# STM32WL3xx register map
File version: 1.0
Registers are 32-bit, read-write, reset 0x0 unless marked. A register's access mark holds for its fields unless they carry their own. Offsets are from the block's base; [hi:lo] are bit positions; {n}, {i} and the like mark numbered series.

## LPUART1 — Universal synchronous asynchronous receiver transmitter (USART)
Base 0x41005000
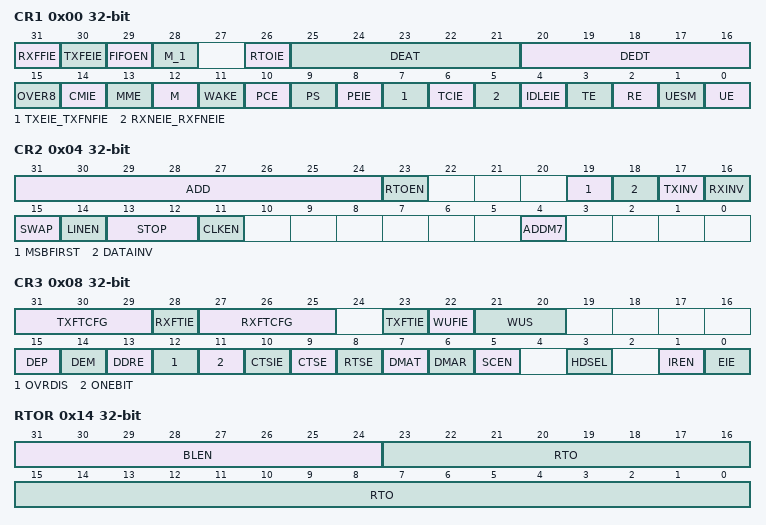
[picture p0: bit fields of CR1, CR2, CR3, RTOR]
0x00 CR1 — (@ 0x00000000) Control register 1
  [31] RXFFIE
  [30] TXFEIE
  [29] FIFOEN
  [28] M_1
  [26] RTOIE
  [25:21] DEAT
  [20:16] DEDT
  [15] OVER8
    0=OVERSAMPLING_16 (Oversampling by 16); 1=OVERSAMPLING_8 (Oversampling by 8)
  [14] CMIE
  [13] MME
  [12] M
  [11] WAKE
    0=IDLELINE (LPUART wake up from Mute mode on Idle Line); 1=ADDRESSMARK (LPUART wake up from Mute mode on Address Mark)
  [10] PCE
  [9] PS
  [8] PEIE
  [7] TXEIE_TXFNFIE
  [6] TCIE
  [5] RXNEIE_RXFNEIE
  [4] IDLEIE
  [3] TE
  [2] RE
  [1] UESM
  [0] UE
0x04 CR2 — (@ 0x00000004) Control register 2
  [31:24] ADD
  [23] RTOEN
  [19] MSBFIRST
    0=LSBFIRST; 1=MSBFIRST
  [18] DATAINV
    0=POSITIVE; 1=NEGATIVE
  [17] TXINV
    0=STANDARD (TX pin signal works using the standard logic levels); 1=INVERTED (TX pin signal values are inverted.)
  [16] RXINV
    0=STANDARD (RX pin signal works using the standard logic levels); 1=INVERTED (RX pin signal values are inverted.)
  [15] SWAP
    0=STANDARD (TX/RX pins are used as defined in standard pinout); 1=SWAPPED (TX and RX pins functions are swapped.)
  [14] LINEN
  [13:12] STOP
    0=STOPBITS_1 (1 stop bit); 2=STOPBITS_2 (2 stop bits); 1=STOPBITS_0_5 (0.5 stop bit); 3=STOPBITS_1_5 (1.5 stop bits)
  [11] CLKEN
  [4] ADDM7
    0=DETECT_4B (4-bit address detection method selected); 1=DETECT_7B (7-bit address detection (in 8-bit data mode) method selected)
0x08 CR3 — (@ 0x00000008) Control register 3
  [31:29] TXFTCFG
  [28] RXFTIE
  [27:25] RXFTCFG
  [23] TXFTIE
  [22] WUFIE
  [21:20] WUS
    0=ADDRESS (Wake up active on address match); 2=STARTBIT (Wake up active on Start bit detection); 3=RXNE (Wake up active on RXNE)
  [15] DEP
    0=HIGH (DE signal is active high); 1=LOW (DE signal is active low)
  [14] DEM
  [13] DDRE
  [12] OVRDIS
  [11] ONEBIT
  [10] CTSIE
  [9] CTSE
  [8] RTSE
  [7] DMAT
  [6] DMAR
  [5] SCEN
  [3] HDSEL
  [1] IREN
  [0] EIE
0x0C BRR — (@ 0x0000000C) Baud rate register
  [19:0] BRR
0x14 RTOR — (@ 0x00000014) Receiver timeout register
  [31:24] BLEN, [23:0] RTO
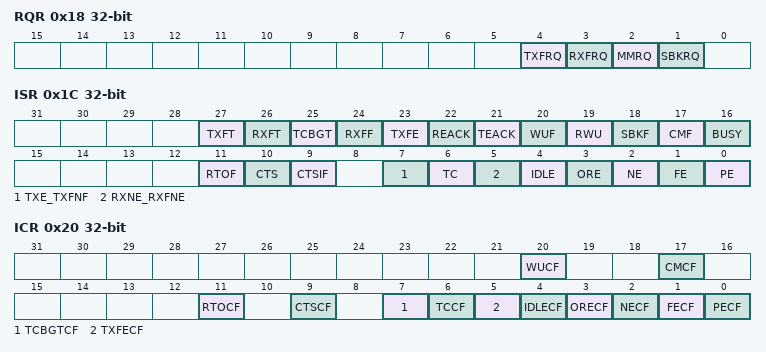
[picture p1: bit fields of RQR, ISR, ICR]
0x18 RQR — (@ 0x00000018) Request register
  [4] TXFRQ, [3] RXFRQ, [2] MMRQ, [1] SBKRQ
0x1C ISR — (@ 0x0000001C) Interrupt & status register
  [27] TXFT, [26] RXFT, [25] TCBGT, [24] RXFF, [23] TXFE, [22] REACK, [21] TEACK, [20] WUF, [19] RWU, [18] SBKF, [17] CMF, [16] BUSY, [11] RTOF, [10] CTS, [9] CTSIF, [7] TXE_TXFNF, [6] TC, [5] RXNE_RXFNE, [4] IDLE, [3] ORE, [2] NE, [1] FE, [0] PE
0x20 ICR — (@ 0x00000020) Interrupt flag clear register
  [20] WUCF, [17] CMCF, [11] RTOCF, [9] CTSCF, [7] TCBGTCF, [6] TCCF, [5] TXFECF, [4] IDLECF, [3] ORECF, [2] NECF, [1] FECF, [0] PECF
0x24 RDR — (@ 0x00000024) Receive data register
  [8:0] RDR
0x28 TDR — (@ 0x00000028) Transmit data register
  [8:0] TDR
0x2C PRESC — (@ 0x0000002C) Prescaler register
  [3:0] PRESCALER
    0=DIV1 (Input clock not divided); 1=DIV2 (Input clock divided by 2); 2=DIV4 (Input clock divided by 4); 3=DIV6; 4=DIV8 (Input clock divided by 8); 5=DIV10; 6=DIV12; 7=DIV16; 8=DIV32 (Input clock divided by 32); 9=DIV64; 10=DIV128; 11=DIV256

## ADC1 — ADC (ADC)
Base 0x41006000
0x00 VERSION_ID — (@ 0x00000000) VERSION_ID register
  [7:0] VERSION_ID
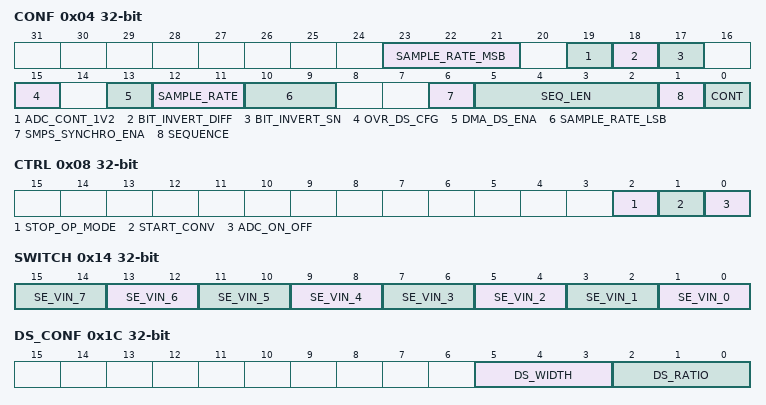
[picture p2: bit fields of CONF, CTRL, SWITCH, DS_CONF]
0x04 CONF — (@ 0x00000004) ADC configuration register
  [23:21] SAMPLE_RATE_MSB
  [19] ADC_CONT_1V2
    0=START; 1=END
  [18] BIT_INVERT_DIFF
  [17] BIT_INVERT_SN
  [15] OVR_DS_CFG
    0=LOST (Previous data is preserved, new data is lost.); 1=KEPT (Previous data is overwritten, new data is kept.)
  [13] DMA_DS_ENA
  [12:11] SAMPLE_RATE
  [10:9] SAMPLE_RATE_LSB
  [6] SMPS_SYNCHRO_ENA
  [5:2] SEQ_LEN
  [1] SEQUENCE
  [0] CONT
0x08 CTRL — (@ 0x00000008) ADC control register
  [2] STOP_OP_MODE, [1] START_CONV, [0] ADC_ON_OFF
0x14 SWITCH — (@ 0x00000014) ADC switch control for Input Selection
  [2n+1:2n] SE_VIN_{n} (n=0..7)
0x1C DS_CONF — (@ 0x0000001C) Downsampler configuration register
  [5:3] DS_WIDTH
  [2:0] DS_RATIO
    0=RATIO_1 (ADC Down Sampler ratio 1, no down sampling (default)); 1=RATIO_2 (ADC Down Sampler ratio 2); 2=RATIO_4 (ADC Down Sampler ratio 4); 3=RATIO_8 (ADC Down Sampler ratio 8); 4=RATIO_16 (ADC Down Sampler ratio 16); 5=RATIO_32 (ADC Down Sampler ratio 32); 6=RATIO_64 (ADC Down Sampler ratio 64); 7=RATIO_128 (ADC Down Sampler ratio 128)
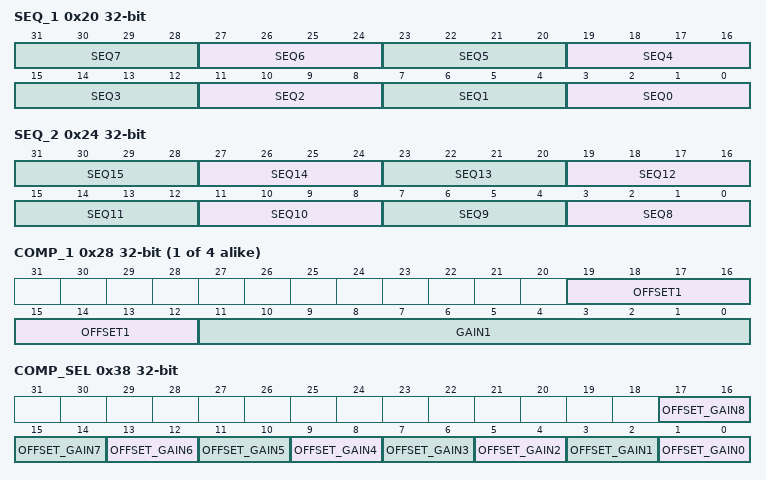
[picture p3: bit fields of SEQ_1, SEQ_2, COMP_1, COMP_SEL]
0x20 SEQ_1 — (@ 0x00000020) ADC regular sequence programming register 1
  [4n+3:4n] SEQ{n} (n=0..7)
0x24 SEQ_2 — (@ 0x00000024) ADC regular sequence programming register 2
  [4n-29:4n-32] SEQ{n} (n=8..15)
{0x24+4i} COMP_{i} (i=1..4) — (@ {0x24+4i}) ADC Gain &
  [19:12] OFFSET{i}, [11:0] GAIN{i}
0x38 COMP_SEL — (@ 0x00000038) ADC Gain &
  [2n+1:2n] OFFSET_GAIN{n} (n=0..8)
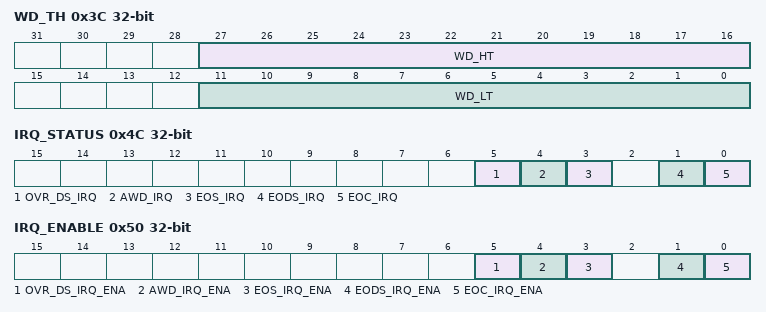
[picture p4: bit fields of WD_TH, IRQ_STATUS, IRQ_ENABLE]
0x3C WD_TH — (@ 0x0000003C) ADC watchdog threshold register register
  [27:16] WD_HT, [11:0] WD_LT
0x40 WD_CONF — (@ 0x00000040) ADC watchdog configuration register
  [15:0] AWD_CHX
    1=VINM0 (ADC watchdog channel selection: VINM0 to negative input); 2=VINM1 (ADC watchdog channel selection: VINM1 to negative input); 4=VINM2 (ADC watchdog channel selection: VINM2 to negative input); 8=VINM3 (ADC watchdog channel selection: VINM3 to negative input); 16=MICROM (ADC watchdog channel selection: MICROM to negative input); 32=VBAT (ADC watchdog channel selection: VBAT to negative input); 64=GND_NEG (ADC watchdog channel selection: GND to negative input); 128=VDDA_NEG (ADC watchdog channel selection: VDDA to negative input); 0x100=VINP0 (ADC watchdog channel selection: VINP0 to positive input); 0x200=VINP1 (ADC watchdog channel selection: VINP1 to positive input); 0x400=VINP2 (ADC watchdog channel selection: VINP2 to positive input); 0x800=VINP3 (ADC watchdog channel selection: VINP3 to positive input); 0x1000=MICROP (ADC watchdog channel selection: MICROP to positive input); 0x2000=TEMPSENSOR (ADC watchdog channel selection: TEMP to positive input); 0x4000=GND_POS (ADC watchdog channel selection: GND to positive input); 0x8000=VDDA_POS (ADC watchdog channel selection: VDDA to positive input)
0x44 DS_DATAOUT — (@ 0x00000044) Downsampler Data output register
  [15:0] DS_DATA
0x4C IRQ_STATUS — (@ 0x0000004C) Interrupt Status register
  [5] OVR_DS_IRQ, [4] AWD_IRQ, [3] EOS_IRQ, [1] EODS_IRQ, [0] EOC_IRQ
0x50 IRQ_ENABLE — (@ 0x00000050) Enable/disable Interrupts
  [5] OVR_DS_IRQ_ENA, [4] AWD_IRQ_ENA, [3] EOS_IRQ_ENA, [1] EODS_IRQ_ENA, [0] EOC_IRQ_ENA
